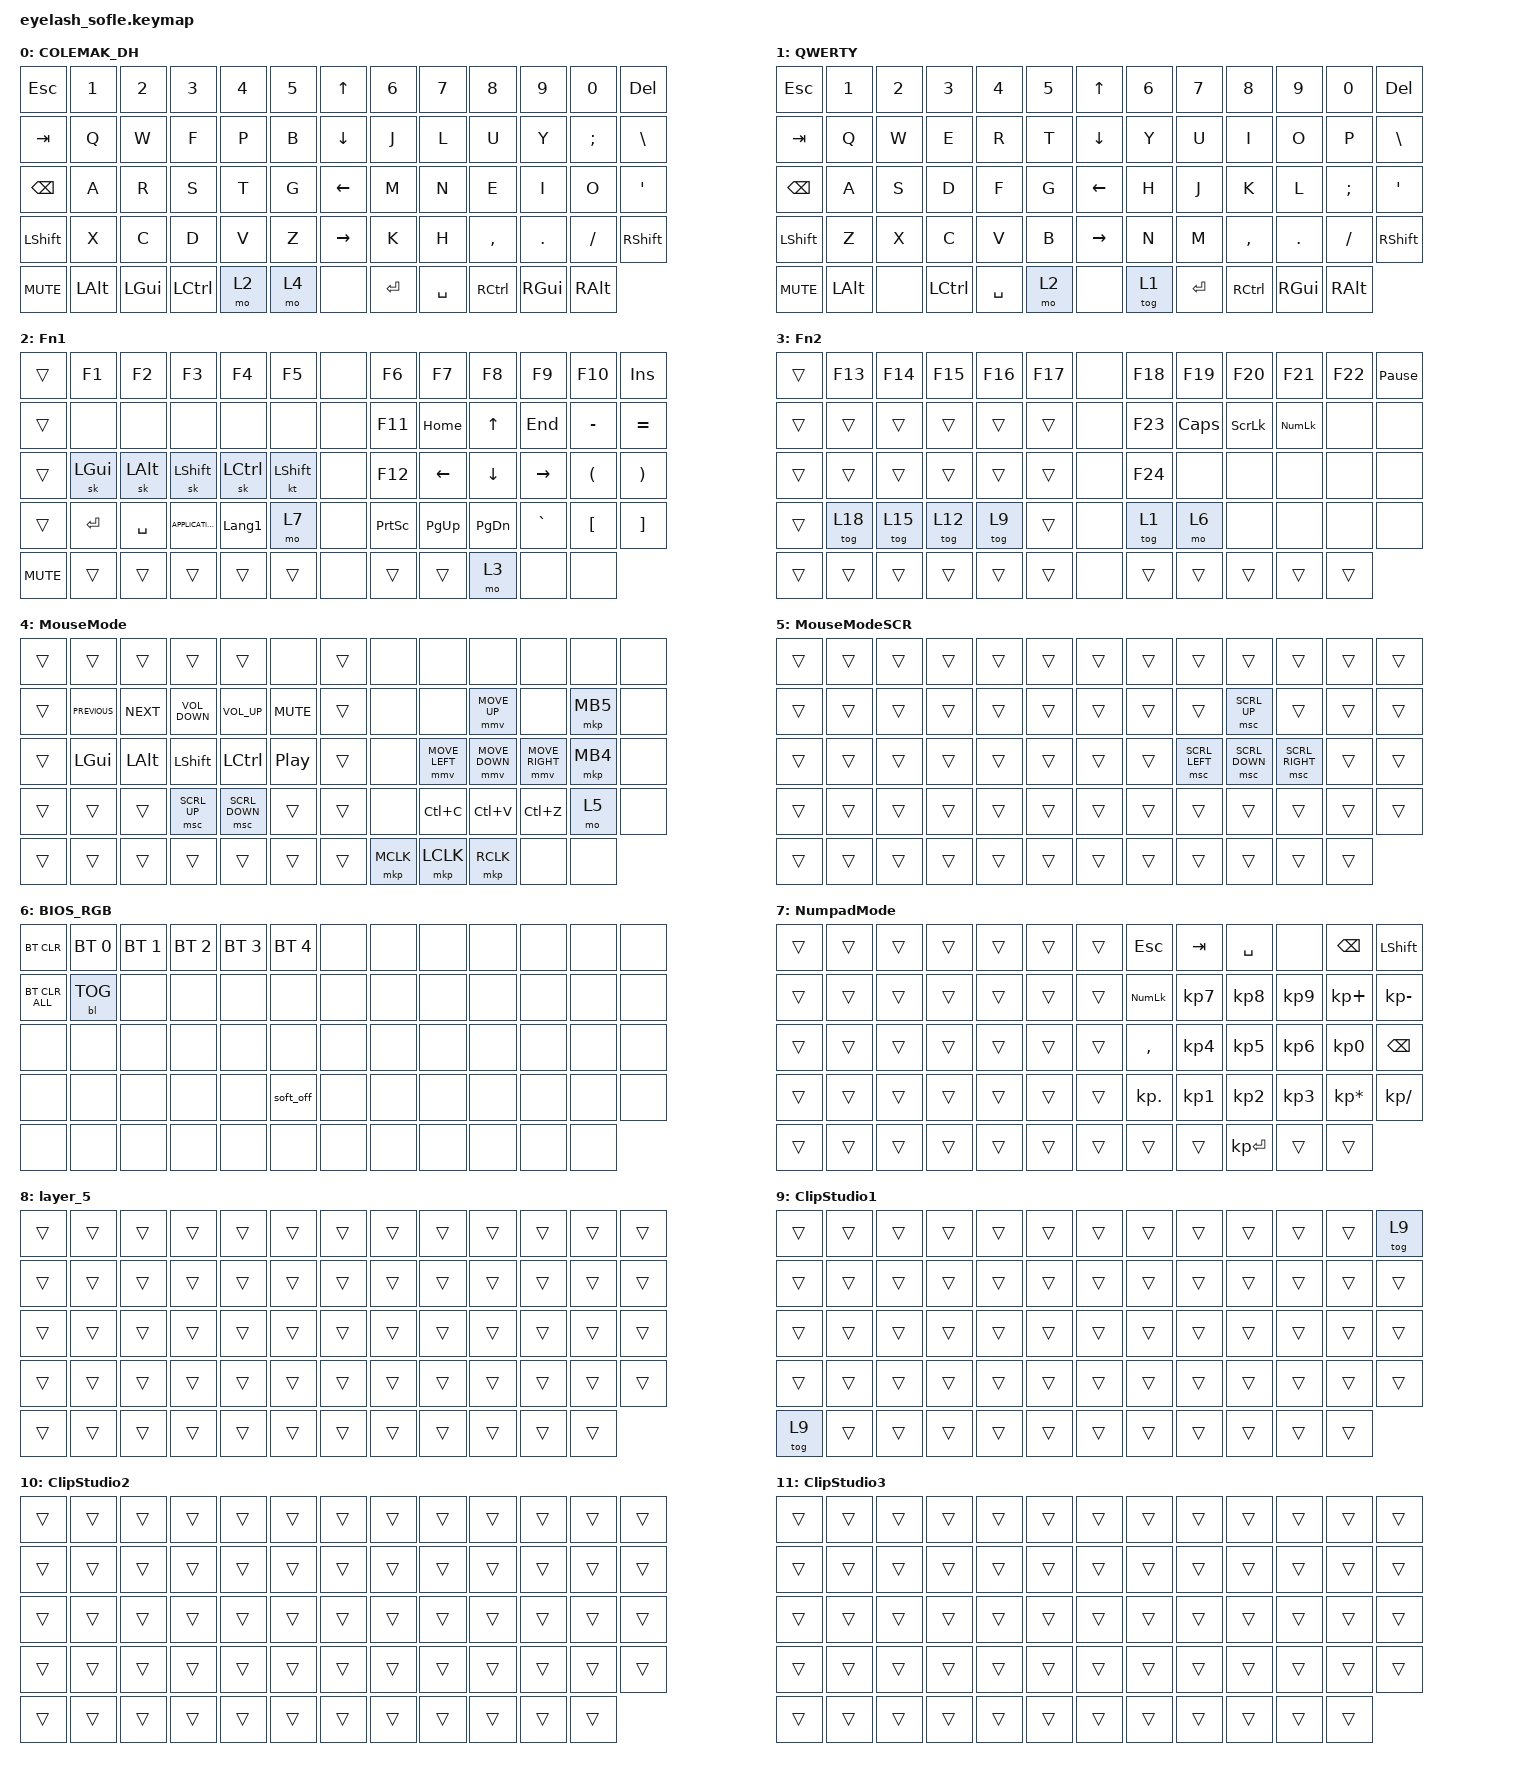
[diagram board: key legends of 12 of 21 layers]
#define ZMK_POINTING_DEFAULT_MOVE_VAL 1200  // 600
#define ZMK_POINTING_DEFAULT_SCRL_VAL 25   // 10

#include <input/processors.dtsi>
#include <zephyr/dt-bindings/input/input-event-codes.h>
#include <behaviors.dtsi>
#include <dt-bindings/zmk/backlight.h>
#include <dt-bindings/zmk/bt.h>
#include <dt-bindings/zmk/keys.h>
#include <dt-bindings/zmk/pointing.h>

&mmv_input_listener { input-processors = <&zip_xy_scaler 2 1>; };

&msc_input_listener { input-processors = <&zip_scroll_scaler 2 1>; };

&msc {
    acceleration-exponent = <1>;      // 0
    time-to-max-speed-ms = <100>;       // 300
    delay-ms = <0>;                   // 0
};

&mmv {
    time-to-max-speed-ms = <500>;
    acceleration-exponent = <1>;
    trigger-period-ms = <16>;
};

&soft_off { hold-time-ms = <2000>; };

/ {
    scroll_encoder: scroll_encoder {
        compatible = "zmk,behavior-sensor-rotate";
        #sensor-binding-cells = <0>;
        bindings = <&msc SCRL_DOWN>, <&msc SCRL_UP>;

        tap-ms = <100>;
    };

    scroll_encoder_v: scroll_encoder_v {
        compatible = "zmk,behavior-sensor-rotate";
        #sensor-binding-cells = <0>;
        bindings = <&msc SCRL_RIGHT>, <&msc SCRL_LEFT>;

        tap-ms = <100>;
        label = "SCROLL_ENCODER_V";
    };

    behaviors {
    };

    combos {
        compatible = "zmk,combos";

        diagonal_ul {
            bindings = <&macro_diagonal_ul>;
            key-positions = <22 34>;
            layers = <4>;
        };

        diagonal_ur {
            bindings = <&macro_diagonal_ur>;
            key-positions = <22 36>;
            layers = <4>;
        };

        diagonal_dl {
            bindings = <&macro_diagonal_dl>;
            key-positions = <34 35>;
            layers = <4>;
        };

        diagonal_dr {
            bindings = <&macro_diagonal_dr>;
            key-positions = <35 36>;
            layers = <4>;
        };
    };

    macros {
        macro_FLStudio_key2midi: Macro_FLStudio_key2midi {
            compatible = "zmk,behavior-macro";
            #binding-cells = <0>;
            bindings = <&tog 14 &kp LC(T)>;
            label = "MACRO_FLSTUDIO_KEY2MIDI";
        };

        macro_diagonal_ul: macro_diagonal_ul {
            compatible = "zmk,behavior-macro";
            #binding-cells = <0>;
            bindings =
                <&macro_press>,
                <&mmv MOVE_UP &mmv MOVE_LEFT>,
                <&macro_pause_for_release>,
                <&macro_release>,
                <&mmv MOVE_UP &mmv MOVE_LEFT>;

            label = "MACRO_DIAGONAL_UL";
        };

        macro_diagonal_ur: macro_diagonal_ur {
            compatible = "zmk,behavior-macro";
            #binding-cells = <0>;
            bindings =
                <&macro_press>,
                <&mmv MOVE_UP &mmv MOVE_RIGHT>,
                <&macro_pause_for_release>,
                <&macro_release>,
                <&mmv MOVE_UP &mmv MOVE_RIGHT>;

            label = "MACRO_DIAGONAL_UR";
        };

        macro_diagonal_dl: macro_diagonal_dl {
            compatible = "zmk,behavior-macro";
            #binding-cells = <0>;
            bindings =
                <&macro_press>,
                <&mmv MOVE_DOWN &mmv MOVE_LEFT>,
                <&macro_pause_for_release>,
                <&macro_release>,
                <&mmv MOVE_DOWN &mmv MOVE_LEFT>;

            label = "MACRO_DIAGONAL_DL";
        };

        macro_diagonal_dr: macro_diagonal_dr {
            compatible = "zmk,behavior-macro";
            #binding-cells = <0>;
            bindings =
                <&macro_press>,
                <&mmv MOVE_DOWN &mmv MOVE_RIGHT>,
                <&macro_pause_for_release>,
                <&macro_release>,
                <&mmv MOVE_DOWN &mmv MOVE_RIGHT>;

            label = "MACRO_DIAGONAL_DR";
        };
    };

    keymap {
        compatible = "zmk,keymap";

        layer_colemak {
            bindings = <
&kp ESC        &kp N1        &kp N2        &kp N3            &kp N4  &kp N5    &kp UP_ARROW     &kp N6     &kp N7     &kp N8             &kp N9         &kp N0         &kp DELETE
&kp TAB        &kp Q         &kp W         &kp F             &kp P   &kp B     &kp DOWN_ARROW   &kp J      &kp L      &kp U              &kp Y          &kp SEMICOLON  &kp BSLH
&kp BACKSPACE  &kp A         &kp R         &kp S             &kp T   &kp G     &kp LEFT_ARROW   &kp M      &kp N      &kp E              &kp I          &kp O          &kp APOS
&kp LSHFT      &kp X         &kp C         &kp D             &kp V   &kp Z     &kp RIGHT_ARROW  &kp K      &kp H      &kp COMMA          &kp DOT        &kp FSLH       &kp RIGHT_SHIFT
&kp C_MUTE     &kp LEFT_ALT  &kp LEFT_GUI  &kp LEFT_CONTROL  &mo 2   &mo 4     &none            &kp ENTER  &kp SPACE  &kp RIGHT_CONTROL  &kp RIGHT_GUI  &kp RIGHT_ALT
            >;

            sensor-bindings = <&inc_dec_kp C_VOLUME_UP C_VOL_DN>;
            display-name = "COLEMAK_DH";
            label = "ColemakDH";
        };

        layer_qwerty {
            bindings = <
&kp ESC     &kp N1        &kp N2  &kp N3     &kp N4     &kp N5    &kp UP_ARROW     &kp N6  &kp N7     &kp N8             &kp N9         &kp N0         &kp DELETE
&kp TAB     &kp Q         &kp W   &kp E      &kp R      &kp T     &kp DOWN         &kp Y   &kp U      &kp I              &kp O          &kp P          &kp BSLH
&kp BSPC    &kp A         &kp S   &kp D      &kp F      &kp G     &kp LEFT_ARROW   &kp H   &kp J      &kp K              &kp L          &kp SEMI       &kp APOS
&kp LSHFT   &kp Z         &kp X   &kp C      &kp V      &kp B     &kp RIGHT_ARROW  &kp N   &kp M      &kp COMMA          &kp DOT        &kp FSLH       &kp RSHFT
&kp C_MUTE  &kp LEFT_ALT  &none   &kp LCTRL  &kp SPACE  &mo 2     &none            &tog 1  &kp ENTER  &kp RIGHT_CONTROL  &kp RIGHT_GUI  &kp RIGHT_ALT
            >;

            label = "QWERTY";
            sensor-bindings = <&inc_dec_kp C_VOLUME_UP C_VOLUME_DOWN>;
        };

        layer_fn1 {
            bindings = <
&trans      &kp F1        &kp F2        &kp F3             &kp F4            &kp F5            &none  &kp F6           &kp F7       &kp F8         &kp F9     &kp F10               &kp INSERT
&trans      &none         &none         &none              &none             &none             &none  &kp F11          &kp HOME     &kp UP         &kp END    &kp MINUS             &kp EQUAL
&trans      &sk LEFT_GUI  &sk LEFT_ALT  &sk LEFT_SHIFT     &sk LEFT_CONTROL  &kt LEFT_SHIFT    &none  &kp F12          &kp LEFT     &kp DOWN       &kp RIGHT  &kp LEFT_PARENTHESIS  &kp RIGHT_PARENTHESIS
&trans      &kp ENTER     &kp SPACE     &kp K_APPLICATION  &kp LANGUAGE_1    &mo 7             &none  &kp PRINTSCREEN  &kp PAGE_UP  &kp PAGE_DOWN  &kp GRAVE  &kp LEFT_BRACKET      &kp RIGHT_BRACKET
&kp C_MUTE  &trans        &trans        &trans             &trans            &trans            &none  &trans           &trans       &mo 3          &none      &none
            >;

            sensor-bindings = <&scroll_encoder>;
            label = "Fn1";
        };

        layer_fn2 {
            bindings = <
&trans  &kp F13  &kp F14  &kp F15  &kp F16  &kp F17    &none  &kp F18  &kp F19   &kp F20         &kp F21         &kp F22  &kp PAUSE_BREAK
&trans  &trans   &trans   &trans   &trans   &trans     &none  &kp F23  &kp CAPS  &kp SCROLLLOCK  &kp KP_NUMLOCK  &none    &none
&trans  &trans   &trans   &trans   &trans   &trans     &none  &kp F24  &none     &none           &none           &none    &none
&trans  &tog 18  &tog 15  &tog 12  &tog 9   &trans     &none  &tog 1   &mo 6     &none           &none           &none    &none
&trans  &trans   &trans   &trans   &trans   &trans     &none  &trans   &trans    &trans          &trans          &trans
            >;

            sensor-bindings = <&scroll_encoder_v>;
            label = "Fn2";
        };

        layer_mouse_mode {
            bindings = <
&trans  &trans          &trans        &trans             &trans            &none               &trans  &none      &none           &none           &none            &none     &none
&trans  &kp C_PREVIOUS  &kp C_NEXT    &kp C_VOLUME_DOWN  &kp C_VOL_UP      &kp C_MUTE          &trans  &none      &none           &mmv MOVE_UP    &none            &mkp MB5  &none
&trans  &kp LEFT_GUI    &kp LEFT_ALT  &kp LEFT_SHIFT     &kp LEFT_CONTROL  &kp C_PLAY_PAUSE    &trans  &none      &mmv MOVE_LEFT  &mmv MOVE_DOWN  &mmv MOVE_RIGHT  &mkp MB4  &none
&trans  &trans          &trans        &msc SCRL_UP       &msc SCRL_DOWN    &trans              &trans  &none      &kp LC(C)       &kp LC(V)       &kp LC(Z)        &mo 5     &none
&trans  &trans          &trans        &trans             &trans            &trans              &trans  &mkp MCLK  &mkp LCLK       &mkp RCLK       &none            &none
            >;

            label = "MouseMode";
            sensor-bindings = <&scroll_encoder>;
        };

        layer_mouse_mode_scroll {
            bindings = <
&trans  &trans  &trans  &trans  &trans  &trans    &trans  &trans  &trans          &trans          &trans           &trans  &trans
&trans  &trans  &trans  &trans  &trans  &trans    &trans  &trans  &trans          &msc SCRL_UP    &trans           &trans  &trans
&trans  &trans  &trans  &trans  &trans  &trans    &trans  &trans  &msc SCRL_LEFT  &msc SCRL_DOWN  &msc SCRL_RIGHT  &trans  &trans
&trans  &trans  &trans  &trans  &trans  &trans    &trans  &trans  &trans          &trans          &trans           &trans  &trans
&trans  &trans  &trans  &trans  &trans  &trans    &trans  &trans  &trans          &trans          &trans           &trans
            >;

            display-name = "MouseModeSCR";
            sensor-bindings = <&scroll_encoder>;
        };

        layer_bios_rgb {
            bindings = <
&bt BT_CLR      &bt BT_SEL 0  &bt BT_SEL 1  &bt BT_SEL 2  &bt BT_SEL 3  &bt BT_SEL 4    &none  &none  &none  &none  &none  &none  &none
&bt BT_CLR_ALL  &bl BL_TOG    &none         &none         &none         &none           &none  &none  &none  &none  &none  &none  &none
&none           &none         &none         &none         &none         &none           &none  &none  &none  &none  &none  &none  &none
&none           &none         &none         &none         &none         &soft_off       &none  &none  &none  &none  &none  &none  &none
&none           &none         &none         &none         &none         &none           &none  &none  &none  &none  &none  &none
            >;

            label = "BIOS_RGB";
        };

        layer_numpad {
            bindings = <
&trans  &trans  &trans  &trans  &trans  &trans    &trans  &kp ESCAPE      &kp TAB          &kp SPACE     &none            &kp BACKSPACE    &kp LEFT_SHIFT
&trans  &trans  &trans  &trans  &trans  &trans    &trans  &kp KP_NUMLOCK  &kp KP_N7        &kp KP_N8     &kp KP_N9        &kp KP_PLUS      &kp KP_MINUS
&trans  &trans  &trans  &trans  &trans  &trans    &trans  &kp COMMA       &kp KP_NUMBER_4  &kp KP_N5     &kp KP_NUMBER_6  &kp KP_N0        &kp BACKSPACE
&trans  &trans  &trans  &trans  &trans  &trans    &trans  &kp KP_DOT      &kp KP_N1        &kp KP_N2     &kp KP_N3        &kp KP_MULTIPLY  &kp KP_DIVIDE
&trans  &trans  &trans  &trans  &trans  &trans    &trans  &trans          &trans           &kp KP_ENTER  &trans           &trans
            >;

            display-name = "NumpadMode";
            sensor-bindings = <&scroll_encoder>;
            label = "Numpad";
        };

        layer_5 {
            bindings = <
&trans  &trans  &trans  &trans  &trans  &trans    &trans  &trans  &trans  &trans  &trans  &trans  &trans
&trans  &trans  &trans  &trans  &trans  &trans    &trans  &trans  &trans  &trans  &trans  &trans  &trans
&trans  &trans  &trans  &trans  &trans  &trans    &trans  &trans  &trans  &trans  &trans  &trans  &trans
&trans  &trans  &trans  &trans  &trans  &trans    &trans  &trans  &trans  &trans  &trans  &trans  &trans
&trans  &trans  &trans  &trans  &trans  &trans    &trans  &trans  &trans  &trans  &trans  &trans
            >;
        };

        ClipStudio1 {
            bindings = <
&trans  &trans  &trans  &trans  &trans  &trans    &trans  &trans  &trans  &trans  &trans  &trans  &tog 9
&trans  &trans  &trans  &trans  &trans  &trans    &trans  &trans  &trans  &trans  &trans  &trans  &trans
&trans  &trans  &trans  &trans  &trans  &trans    &trans  &trans  &trans  &trans  &trans  &trans  &trans
&trans  &trans  &trans  &trans  &trans  &trans    &trans  &trans  &trans  &trans  &trans  &trans  &trans
&tog 9  &trans  &trans  &trans  &trans  &trans    &trans  &trans  &trans  &trans  &trans  &trans
            >;

            label = "ClipStudio1";
        };

        ClipStudio2 {
            bindings = <
&trans  &trans  &trans  &trans  &trans  &trans    &trans  &trans  &trans  &trans  &trans  &trans  &trans
&trans  &trans  &trans  &trans  &trans  &trans    &trans  &trans  &trans  &trans  &trans  &trans  &trans
&trans  &trans  &trans  &trans  &trans  &trans    &trans  &trans  &trans  &trans  &trans  &trans  &trans
&trans  &trans  &trans  &trans  &trans  &trans    &trans  &trans  &trans  &trans  &trans  &trans  &trans
&trans  &trans  &trans  &trans  &trans  &trans    &trans  &trans  &trans  &trans  &trans  &trans
            >;

            label = "ClipStudio2";
        };

        ClipStudio3 {
            bindings = <
&trans  &trans  &trans  &trans  &trans  &trans    &trans  &trans  &trans  &trans  &trans  &trans  &trans
&trans  &trans  &trans  &trans  &trans  &trans    &trans  &trans  &trans  &trans  &trans  &trans  &trans
&trans  &trans  &trans  &trans  &trans  &trans    &trans  &trans  &trans  &trans  &trans  &trans  &trans
&trans  &trans  &trans  &trans  &trans  &trans    &trans  &trans  &trans  &trans  &trans  &trans  &trans
&trans  &trans  &trans  &trans  &trans  &trans    &trans  &trans  &trans  &trans  &trans  &trans
            >;

            label = "ClipStudio3";
        };

        FLStudio1 {
            bindings = <
&kp ESC         &trans            &trans     &trans        &trans         &trans                      &trans  &trans  &trans  &trans  &trans  &trans  &tog 12
&trans          &kp LC(S)         &trans     &trans        &kp LC(LA(Z))  &kp LC(T)                   &trans  &trans  &trans  &trans  &trans  &trans  &trans
&kp DEL         &kp S             &kp C      &kp B         &kp P          &kp M                       &none   &trans  &trans  &trans  &trans  &trans  &trans
&kp LEFT_SHIFT  &kp DEL           &kp LC(B)  &kp LC(C)     &kp LC(V)      &trans                      &trans  &trans  &trans  &trans  &trans  &trans  &trans
&tog 12         &sk LEFT_CONTROL  &trans     &kp LEFT_ALT  &lt 13 SPACE   &macro_FLStudio_key2midi    &trans  &trans  &trans  &trans  &trans  &trans
            >;

            label = "FLStudio1";
            sensor-bindings = <&inc_dec_kp C_VOL_UP C_VOLUME_DOWN>;
        };

        FLStudio2 {
            bindings = <
&trans  &kp F5     &kp F6     &kp F7     &kp F9     &kp F12      &trans  &trans  &trans  &trans  &trans  &trans  &trans
&trans  &kp LC(Q)  &kp LA(R)  &kp LA(S)  &kp LC(L)  &kp LC(A)    &trans  &trans  &trans  &trans  &trans  &trans  &trans
&trans  &trans     &trans     &trans     &trans     &trans       &trans  &trans  &trans  &trans  &trans  &trans  &trans
&trans  &trans     &trans     &trans     &trans     &trans       &trans  &trans  &trans  &trans  &trans  &trans  &trans
&trans  &trans     &trans     &trans     &trans     &trans       &trans  &trans  &trans  &trans  &trans  &trans
            >;

            label = "FLStudio2";
            sensor-bindings = <&scroll_encoder>;
        };

        FLStudio3 {
            bindings = <
&trans  &kp N1  &kp N2  &kp N3  &kp N4  &kp N5                      &kp N5  &kp N6  &kp N7  &kp N8     &kp N9   &kp N0    &trans
&trans  &kp Q   &kp W   &kp E   &kp R   &kp T                       &kp Y   &kp Y   &kp U   &kp I      &kp O    &kp P     &trans
&trans  &kp A   &kp S   &kp D   &kp F   &kp G                       &kp G   &kp H   &kp J   &kp K      &kp L    &kp SEMI  &trans
&trans  &kp Z   &kp X   &kp C   &kp V   &kp B                       &kp N   &kp N   &kp M   &kp COMMA  &kp DOT  &kp FSLH  &trans
&trans  &trans  &trans  &trans  &trans  &macro_FLStudio_key2midi    &trans  &trans  &trans  &trans     &trans   &trans
            >;

            label = "FLStudio3";
        };

        layer_15 {
            bindings = <
&trans   &trans  &trans  &trans  &trans  &trans    &trans  &trans  &trans  &trans  &trans  &trans  &tog 15
&trans   &trans  &trans  &trans  &trans  &trans    &trans  &trans  &trans  &trans  &trans  &trans  &trans
&trans   &trans  &trans  &trans  &trans  &trans    &trans  &trans  &trans  &trans  &trans  &trans  &trans
&trans   &trans  &trans  &trans  &trans  &trans    &trans  &trans  &trans  &trans  &trans  &trans  &trans
&tog 15  &trans  &trans  &trans  &trans  &trans    &trans  &trans  &trans  &trans  &trans  &trans
            >;
        };

        layer_16 {
            bindings = <
&trans  &trans  &trans  &trans  &trans  &trans    &trans  &trans  &trans  &trans  &trans  &trans  &trans
&trans  &trans  &trans  &trans  &trans  &trans    &trans  &trans  &trans  &trans  &trans  &trans  &trans
&trans  &trans  &trans  &trans  &trans  &trans    &trans  &trans  &trans  &trans  &trans  &trans  &trans
&trans  &trans  &trans  &trans  &trans  &trans    &trans  &trans  &trans  &trans  &trans  &trans  &trans
&trans  &trans  &trans  &trans  &trans  &trans    &trans  &trans  &trans  &trans  &trans  &trans
            >;
        };

        layer_17 {
            bindings = <
&trans  &trans  &trans  &trans  &trans  &trans    &trans  &trans  &trans  &trans  &trans  &trans  &trans
&trans  &trans  &trans  &trans  &trans  &trans    &trans  &trans  &trans  &trans  &trans  &trans  &trans
&trans  &trans  &trans  &trans  &trans  &trans    &trans  &trans  &trans  &trans  &trans  &trans  &trans
&trans  &trans  &trans  &trans  &trans  &trans    &trans  &trans  &trans  &trans  &trans  &trans  &trans
&trans  &trans  &trans  &trans  &trans  &trans    &trans  &trans  &trans  &trans  &trans  &trans
            >;
        };

        layer_18 {
            bindings = <
&trans   &trans  &trans  &trans  &trans  &trans    &trans  &trans  &trans  &trans  &trans  &trans  &tog 18
&trans   &trans  &trans  &trans  &trans  &trans    &trans  &trans  &trans  &trans  &trans  &trans  &trans
&trans   &trans  &trans  &trans  &trans  &trans    &trans  &trans  &trans  &trans  &trans  &trans  &trans
&trans   &trans  &trans  &trans  &trans  &trans    &trans  &trans  &trans  &trans  &trans  &trans  &trans
&tog 18  &trans  &trans  &trans  &trans  &trans    &trans  &trans  &trans  &trans  &trans  &trans
            >;
        };

        layer_19 {
            bindings = <
&trans  &trans  &trans  &trans  &trans  &trans    &trans  &trans  &trans  &trans  &trans  &trans  &trans
&trans  &trans  &trans  &trans  &trans  &trans    &trans  &trans  &trans  &trans  &trans  &trans  &trans
&trans  &trans  &trans  &trans  &trans  &trans    &trans  &trans  &trans  &trans  &trans  &trans  &trans
&trans  &trans  &trans  &trans  &trans  &trans    &trans  &trans  &trans  &trans  &trans  &trans  &trans
&trans  &trans  &trans  &trans  &trans  &trans    &trans  &trans  &trans  &trans  &trans  &trans
            >;
        };

        layer_20 {
            bindings = <
&trans  &trans  &trans  &trans  &trans  &trans    &trans  &trans  &trans  &trans  &trans  &trans  &trans
&trans  &trans  &trans  &trans  &trans  &trans    &trans  &trans  &trans  &trans  &trans  &trans  &trans
&trans  &trans  &trans  &trans  &trans  &trans    &trans  &trans  &trans  &trans  &trans  &trans  &trans
&trans  &trans  &trans  &trans  &trans  &trans    &trans  &trans  &trans  &trans  &trans  &trans  &trans
&trans  &trans  &trans  &trans  &trans  &trans    &trans  &trans  &trans  &trans  &trans  &trans
            >;
        };
    };
};
